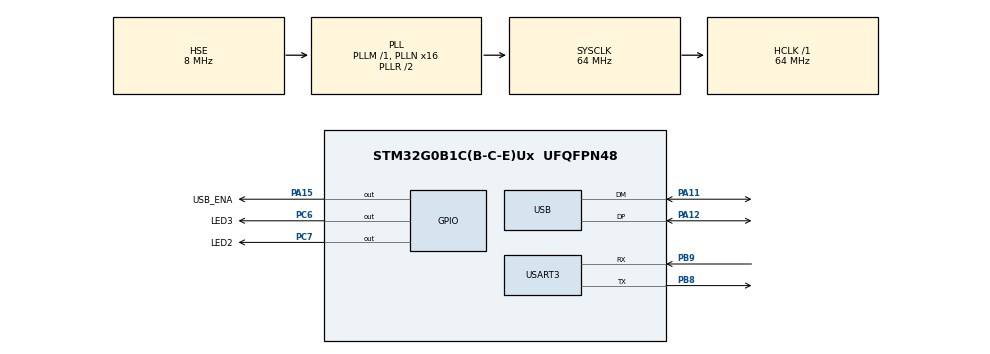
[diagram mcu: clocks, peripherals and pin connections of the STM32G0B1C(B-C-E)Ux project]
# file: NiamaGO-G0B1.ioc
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Mcu.Family=STM32G0
Mcu.Name=STM32G0B1C(B-C-E)Ux
Mcu.Package=UFQFPN48
NVIC.USB_UCPD1_2_IRQn=true\:0\:0\:false\:false\:true\:true\:true\:true
PA11\ [PA9].Mode=Device
PA11\ [PA9].Signal=USB_DM
PA12\ [PA10].Mode=Device
PA12\ [PA10].Signal=USB_DP
PA13.Mode=Serial_Wire
PA13.Signal=SYS_SWDIO
PA14-BOOT0.Mode=Serial_Wire
PA14-BOOT0.Signal=SYS_SWCLK
PA15.GPIO_Label=USB_ENA
PA15.GPIO_PuPd=GPIO_NOPULL
PA15.PinState=GPIO_PIN_SET
PA15.Signal=GPIO_Output
PB8.Mode=Asynchronous
PB8.Signal=USART3_TX
PB9.Mode=Asynchronous
PB9.Signal=USART3_RX
PC6.GPIO_Label=LED3
PC6.Signal=GPIO_Output
PC7.GPIO_Label=LED2
PC7.Signal=GPIO_Output
PF0-OSC_IN\ (PF0).Mode=HSE-External-Oscillator
PF0-OSC_IN\ (PF0).Signal=RCC_OSC_IN
PF1-OSC_OUT\ (PF1).Mode=HSE-External-Oscillator
PF1-OSC_OUT\ (PF1).Signal=RCC_OSC_OUT
ProjectManager.HeapSize=0x200
ProjectManager.StackSize=0x400
ProjectManager.TargetToolchain=STM32CubeIDE
RCC.ADCFreq_Value=64000000
RCC.AHBFreq_Value=64000000
RCC.CortexFreq_Value=64000000
RCC.EXTERNAL_CLOCK_VALUE=48000
RCC.HCLKFreq_Value=64000000
RCC.HSE_VALUE=8000000
RCC.HSI48_VALUE=48000000
RCC.HSI_VALUE=16000000
RCC.LSE_VALUE=32768
RCC.PLLN=16
RCC.PLLSourceVirtual=RCC_PLLSOURCE_HSE
RCC.SYSCLKFreq_VALUE=64000000
RCC.SYSCLKSource=RCC_SYSCLKSOURCE_PLLCLK
RCC.USBFreq_Value=48000000
RCC.VCOOutputFreq_Value=128000000
USART3.VirtualMode-Asynchronous=VM_ASYNC
USB_DEVICE.CLASS_NAME_FS=CDC
USB_DEVICE.MANUFACTURER_STRING=NiamaGO.com
USB_DEVICE.PRODUCT_STRING_CDC_FS=NiamaGO Virtual ComPort
USB_DEVICE.VirtualMode=Cdc
USB_DEVICE.VirtualModeFS=Cdc_FS
USB_DRD_FS.low_power_enable=DISABLE
VP_CRC_VS_CRC.Mode=CRC_Activate
VP_SYS_VS_DBSignals.Mode=DisableDeadBatterySignals
VP_USB_DEVICE_VS_USB_DEVICE_CDC_FS.Mode=CDC_FS
board=custom

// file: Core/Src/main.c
/* USER CODE BEGIN Header */
/**
  ******************************************************************************
  * @file           : main.c
  * @brief          : Main program body
  ******************************************************************************
  * @attention
  *
  * Copyright (c) 2022 STMicroelectronics.
  * All rights reserved.
  *
  * This software is licensed under terms that can be found in the LICENSE file
  * in the root directory of this software component.
  * If no LICENSE file comes with this software, it is provided AS-IS.
  *
  ******************************************************************************
  */
/* USER CODE END Header */
#include "main.h"
#include "usb_device.h"

/* USER CODE BEGIN Includes */
#include <stdio.h>
#include "debug.h"
/* USER CODE END Includes */

 CRC_HandleTypeDef hcrc;

UART_HandleTypeDef huart3;

void SystemClock_Config(void);
static void MX_GPIO_Init(void);
static void MX_USART3_UART_Init(void);
static void MX_CRC_Init(void);

int main(void)
{

  /* MCU Configuration--------------------------------------------------------*/

  /* Reset of all peripherals, Initializes the Flash interface and the Systick. */
  HAL_Init();

  /* Configure the system clock */
  SystemClock_Config();

  /* Initialize all configured peripherals */
  MX_GPIO_Init();
  MX_USART3_UART_Init();
  MX_CRC_Init();
  MX_USB_Device_Init();
  /* USER CODE BEGIN 2 */

  printf("NiamaGO: Init done!\n");

  /* USER CODE END 2 */

  /* Infinite loop */
  /* USER CODE BEGIN WHILE */
  while (1)
  {
    // LED2 on, LED3 off
	HAL_GPIO_WritePin(LED2_GPIO_Port, LED2_Pin, GPIO_PIN_SET);
  	HAL_GPIO_WritePin(LED3_GPIO_Port, LED3_Pin, GPIO_PIN_RESET);

	HAL_Delay(500);

    // LED2 off, LED3 on
	HAL_GPIO_WritePin(LED2_GPIO_Port, LED2_Pin, GPIO_PIN_RESET);
  	HAL_GPIO_WritePin(LED3_GPIO_Port, LED3_Pin, GPIO_PIN_SET);

	HAL_Delay(500);

    /* USER CODE END WHILE */

  }
}

void SystemClock_Config(void)
{
  RCC_OscInitTypeDef RCC_OscInitStruct = {0};
  RCC_ClkInitTypeDef RCC_ClkInitStruct = {0};

  /** Configure the main internal regulator output voltage
  */
  HAL_PWREx_ControlVoltageScaling(PWR_REGULATOR_VOLTAGE_SCALE1);

  /** Initializes the RCC Oscillators according to the specified parameters
  * in the RCC_OscInitTypeDef structure.
  */
  RCC_OscInitStruct.OscillatorType = RCC_OSCILLATORTYPE_HSE|RCC_OSCILLATORTYPE_HSI48;
  RCC_OscInitStruct.HSEState = RCC_HSE_ON;
  RCC_OscInitStruct.HSI48State = RCC_HSI48_ON;
  RCC_OscInitStruct.PLL.PLLState = RCC_PLL_ON;
  RCC_OscInitStruct.PLL.PLLSource = RCC_PLLSOURCE_HSE;
  RCC_OscInitStruct.PLL.PLLM = RCC_PLLM_DIV1;
  RCC_OscInitStruct.PLL.PLLN = 16;
  RCC_OscInitStruct.PLL.PLLP = RCC_PLLP_DIV2;
  RCC_OscInitStruct.PLL.PLLQ = RCC_PLLQ_DIV2;
  RCC_OscInitStruct.PLL.PLLR = RCC_PLLR_DIV2;
  if (HAL_RCC_OscConfig(&RCC_OscInitStruct) != HAL_OK)
  {
    Error_Handler();
  }

  /** Initializes the CPU, AHB and APB buses clocks
  */
  RCC_ClkInitStruct.ClockType = RCC_CLOCKTYPE_HCLK|RCC_CLOCKTYPE_SYSCLK
                              |RCC_CLOCKTYPE_PCLK1;
  RCC_ClkInitStruct.SYSCLKSource = RCC_SYSCLKSOURCE_PLLCLK;
  RCC_ClkInitStruct.AHBCLKDivider = RCC_SYSCLK_DIV1;
  RCC_ClkInitStruct.APB1CLKDivider = RCC_HCLK_DIV1;

  if (HAL_RCC_ClockConfig(&RCC_ClkInitStruct, FLASH_LATENCY_2) != HAL_OK)
  {
    Error_Handler();
  }
}

static void MX_CRC_Init(void)
{

  hcrc.Instance = CRC;
  hcrc.Init.DefaultPolynomialUse = DEFAULT_POLYNOMIAL_ENABLE;
  hcrc.Init.DefaultInitValueUse = DEFAULT_INIT_VALUE_ENABLE;
  hcrc.Init.InputDataInversionMode = CRC_INPUTDATA_INVERSION_NONE;
  hcrc.Init.OutputDataInversionMode = CRC_OUTPUTDATA_INVERSION_DISABLE;
  hcrc.InputDataFormat = CRC_INPUTDATA_FORMAT_BYTES;
  if (HAL_CRC_Init(&hcrc) != HAL_OK)
  {
    Error_Handler();
  }

}

static void MX_USART3_UART_Init(void)
{

  huart3.Instance = USART3;
  huart3.Init.BaudRate = 115200;
  huart3.Init.WordLength = UART_WORDLENGTH_8B;
  huart3.Init.StopBits = UART_STOPBITS_1;
  huart3.Init.Parity = UART_PARITY_NONE;
  huart3.Init.Mode = UART_MODE_TX_RX;
  huart3.Init.HwFlowCtl = UART_HWCONTROL_NONE;
  huart3.Init.OverSampling = UART_OVERSAMPLING_16;
  huart3.Init.OneBitSampling = UART_ONE_BIT_SAMPLE_DISABLE;
  huart3.Init.ClockPrescaler = UART_PRESCALER_DIV1;
  huart3.AdvancedInit.AdvFeatureInit = UART_ADVFEATURE_NO_INIT;
  if (HAL_UART_Init(&huart3) != HAL_OK)
  {
    Error_Handler();
  }
  if (HAL_UARTEx_SetTxFifoThreshold(&huart3, UART_TXFIFO_THRESHOLD_1_8) != HAL_OK)
  {
    Error_Handler();
  }
  if (HAL_UARTEx_SetRxFifoThreshold(&huart3, UART_RXFIFO_THRESHOLD_1_8) != HAL_OK)
  {
    Error_Handler();
  }
  if (HAL_UARTEx_DisableFifoMode(&huart3) != HAL_OK)
  {
    Error_Handler();
  }

}

static void MX_GPIO_Init(void)
{
  GPIO_InitTypeDef GPIO_InitStruct = {0};

  /* GPIO Ports Clock Enable */
  __HAL_RCC_GPIOF_CLK_ENABLE();
  __HAL_RCC_GPIOC_CLK_ENABLE();
  __HAL_RCC_GPIOA_CLK_ENABLE();
  __HAL_RCC_GPIOB_CLK_ENABLE();

  /*Configure GPIO pin Output Level */
  HAL_GPIO_WritePin(GPIOC, LED3_Pin|LED2_Pin, GPIO_PIN_RESET);

  /*Configure GPIO pin Output Level */
  HAL_GPIO_WritePin(USB_ENA_GPIO_Port, USB_ENA_Pin, GPIO_PIN_SET);

  /*Configure GPIO pins : LED3_Pin LED2_Pin */
  GPIO_InitStruct.Pin = LED3_Pin|LED2_Pin;
  GPIO_InitStruct.Mode = GPIO_MODE_OUTPUT_PP;
  GPIO_InitStruct.Pull = GPIO_NOPULL;
  GPIO_InitStruct.Speed = GPIO_SPEED_FREQ_LOW;
  HAL_GPIO_Init(GPIOC, &GPIO_InitStruct);

  /*Configure GPIO pin : USB_ENA_Pin */
  GPIO_InitStruct.Pin = USB_ENA_Pin;
  GPIO_InitStruct.Mode = GPIO_MODE_OUTPUT_PP;
  GPIO_InitStruct.Pull = GPIO_NOPULL;
  GPIO_InitStruct.Speed = GPIO_SPEED_FREQ_LOW;
  HAL_GPIO_Init(USB_ENA_GPIO_Port, &GPIO_InitStruct);

}

void Error_Handler(void)
{
  __disable_irq();
  while (1)
  {
  }
}
